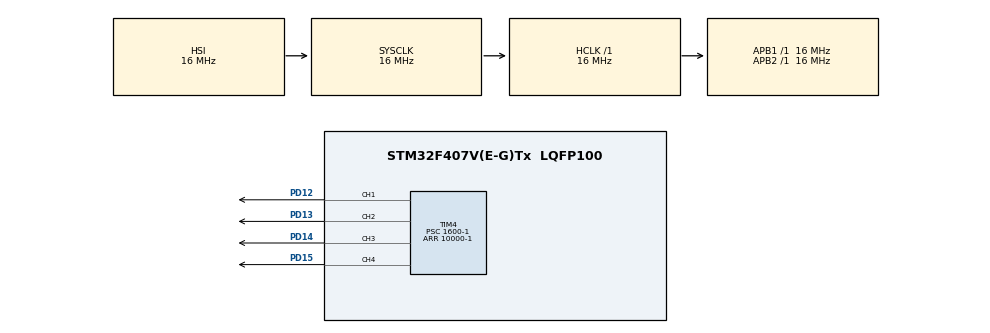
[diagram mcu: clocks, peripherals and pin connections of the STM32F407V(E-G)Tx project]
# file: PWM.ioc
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Mcu.Family=STM32F4
Mcu.Name=STM32F407V(E-G)Tx
Mcu.Package=LQFP100
NVIC.PriorityGroup=NVIC_PRIORITYGROUP_4
PD12.Signal=S_TIM4_CH1
PD13.Signal=S_TIM4_CH2
PD14.Signal=S_TIM4_CH3
PD15.Signal=S_TIM4_CH4
PH0-OSC_IN.Mode=HSE-External-Oscillator
PH0-OSC_IN.Signal=RCC_OSC_IN
PH1-OSC_OUT.Mode=HSE-External-Oscillator
PH1-OSC_OUT.Signal=RCC_OSC_OUT
ProjectManager.HeapSize=0x200
ProjectManager.StackSize=0x400
ProjectManager.TargetToolchain=STM32CubeIDE
RCC.AHBFreq_Value=16000000
RCC.APB1Freq_Value=16000000
RCC.APB2Freq_Value=16000000
RCC.CortexFreq_Value=16000000
RCC.HSE_VALUE=25000000
RCC.HSI_VALUE=16000000
RCC.LSE_VALUE=32768
RCC.SYSCLKFreq_VALUE=16000000
RCC.VCOOutputFreq_Value=192000000
SH.S_TIM4_CH1.0=TIM4_CH1,PWM Generation1 CH1
SH.S_TIM4_CH2.0=TIM4_CH2,PWM Generation2 CH2
SH.S_TIM4_CH3.0=TIM4_CH3,PWM Generation3 CH3
SH.S_TIM4_CH4.0=TIM4_CH4,PWM Generation4 CH4
TIM4.Channel-PWM\ Generation1\ CH1=TIM_CHANNEL_1
TIM4.Channel-PWM\ Generation2\ CH2=TIM_CHANNEL_2
TIM4.Channel-PWM\ Generation3\ CH3=TIM_CHANNEL_3
TIM4.Channel-PWM\ Generation4\ CH4=TIM_CHANNEL_4
TIM4.Period=10000-1
TIM4.Prescaler=1600-1
board=custom

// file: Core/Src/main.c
/* USER CODE BEGIN Header */
/**
  ******************************************************************************
  * @file           : main.c
  * @brief          : Main program body
  ******************************************************************************
  * @attention
  *
  * Copyright (c) 2024 STMicroelectronics.
  * All rights reserved.
  *
  * This software is licensed under terms that can be found in the LICENSE file
  * in the root directory of this software component.
  * If no LICENSE file comes with this software, it is provided AS-IS.
  *
  ******************************************************************************
  */
/* USER CODE END Header */
#include "main.h"

TIM_HandleTypeDef htim4;

/* USER CODE BEGIN PV */
float duty_c;
int c=0;
/* USER CODE END PV */

void SystemClock_Config(void);
static void MX_GPIO_Init(void);
static void MX_TIM4_Init(void);

int main(void)
{

  /* MCU Configuration--------------------------------------------------------*/

  /* Reset of all peripherals, Initializes the Flash interface and the Systick. */
  HAL_Init();

  /* Configure the system clock */
  SystemClock_Config();

  /* Initialize all configured peripherals */
  MX_GPIO_Init();
  MX_TIM4_Init();
  /* USER CODE BEGIN 2 */
  HAL_TIM_PWM_Start(&htim4,TIM_CHANNEL_1);
  HAL_TIM_PWM_Start(&htim4,TIM_CHANNEL_2);
  HAL_TIM_PWM_Start(&htim4,TIM_CHANNEL_3);
  HAL_TIM_PWM_Start(&htim4,TIM_CHANNEL_4);
  //HAL_GPIO_WritePin(GPIOD,GPIO_PIN_15,1);
  /* USER CODE END 2 */

  /* Infinite loop */
  while (1)
  {

    /* USER CODE BEGIN 3 */
	  for(duty_c=0;duty_c<=1000;duty_c++)
	  {
		  __HAL_TIM_SET_COMPARE(&htim4,0x00000000U+(c*4),duty_c);
		  HAL_Delay(2);
	  }

	  for(duty_c=1000;duty_c>=0;duty_c--)
	  {
		  __HAL_TIM_SET_COMPARE(&htim4,0x00000000U+(c*4),duty_c);
		   (2);
	  }

	  c=(c+1)%4;

  }
  /* USER CODE END 3 */
}

void SystemClock_Config(void)
{
  RCC_OscInitTypeDef RCC_OscInitStruct = {0};
  RCC_ClkInitTypeDef RCC_ClkInitStruct = {0};

  /** Configure the main internal regulator output voltage
  */
  __HAL_RCC_PWR_CLK_ENABLE();
  __HAL_PWR_VOLTAGESCALING_CONFIG(PWR_REGULATOR_VOLTAGE_SCALE1);

  /** Initializes the RCC Oscillators according to the specified parameters
  * in the RCC_OscInitTypeDef structure.
  */
  RCC_OscInitStruct.OscillatorType = RCC_OSCILLATORTYPE_HSI;
  RCC_OscInitStruct.HSIState = RCC_HSI_ON;
  RCC_OscInitStruct.HSICalibrationValue = RCC_HSICALIBRATION_DEFAULT;
  RCC_OscInitStruct.PLL.PLLState = RCC_PLL_NONE;
  if (HAL_RCC_OscConfig(&RCC_OscInitStruct) != HAL_OK)
  {
    Error_Handler();
  }

  /** Initializes the CPU, AHB and APB buses clocks
  */
  RCC_ClkInitStruct.ClockType = RCC_CLOCKTYPE_HCLK|RCC_CLOCKTYPE_SYSCLK
                              |RCC_CLOCKTYPE_PCLK1|RCC_CLOCKTYPE_PCLK2;
  RCC_ClkInitStruct.SYSCLKSource = RCC_SYSCLKSOURCE_HSI;
  RCC_ClkInitStruct.AHBCLKDivider = RCC_SYSCLK_DIV1;
  RCC_ClkInitStruct.APB1CLKDivider = RCC_HCLK_DIV1;
  RCC_ClkInitStruct.APB2CLKDivider = RCC_HCLK_DIV1;

  if (HAL_RCC_ClockConfig(&RCC_ClkInitStruct, FLASH_LATENCY_0) != HAL_OK)
  {
    Error_Handler();
  }
}

static void MX_TIM4_Init(void)
{

  TIM_MasterConfigTypeDef sMasterConfig = {0};
  TIM_OC_InitTypeDef sConfigOC = {0};

  htim4.Instance = TIM4;
  htim4.Init.Prescaler = 1600-1;
  htim4.Init.CounterMode = TIM_COUNTERMODE_UP;
  htim4.Init.Period = 10000-1;
  htim4.Init.ClockDivision = TIM_CLOCKDIVISION_DIV1;
  htim4.Init.AutoReloadPreload = TIM_AUTORELOAD_PRELOAD_DISABLE;
  if (HAL_TIM_PWM_Init(&htim4) != HAL_OK)
  {
    Error_Handler();
  }
  sMasterConfig.MasterOutputTrigger = TIM_TRGO_RESET;
  sMasterConfig.MasterSlaveMode = TIM_MASTERSLAVEMODE_DISABLE;
  if (HAL_TIMEx_MasterConfigSynchronization(&htim4, &sMasterConfig) != HAL_OK)
  {
    Error_Handler();
  }
  sConfigOC.OCMode = TIM_OCMODE_PWM1;
  sConfigOC.Pulse = 0;
  sConfigOC.OCPolarity = TIM_OCPOLARITY_HIGH;
  sConfigOC.OCFastMode = TIM_OCFAST_DISABLE;
  if (HAL_TIM_PWM_ConfigChannel(&htim4, &sConfigOC, TIM_CHANNEL_1) != HAL_OK)
  {
    Error_Handler();
  }
  if (HAL_TIM_PWM_ConfigChannel(&htim4, &sConfigOC, TIM_CHANNEL_2) != HAL_OK)
  {
    Error_Handler();
  }
  if (HAL_TIM_PWM_ConfigChannel(&htim4, &sConfigOC, TIM_CHANNEL_3) != HAL_OK)
  {
    Error_Handler();
  }
  if (HAL_TIM_PWM_ConfigChannel(&htim4, &sConfigOC, TIM_CHANNEL_4) != HAL_OK)
  {
    Error_Handler();
  }
  HAL_TIM_MspPostInit(&htim4);

}

static void MX_GPIO_Init(void)
{

  /* GPIO Ports Clock Enable */
  __HAL_RCC_GPIOH_CLK_ENABLE();
  __HAL_RCC_GPIOD_CLK_ENABLE();

}

void Error_Handler(void)
{
  __disable_irq();
  while (1)
  {
  }
}
